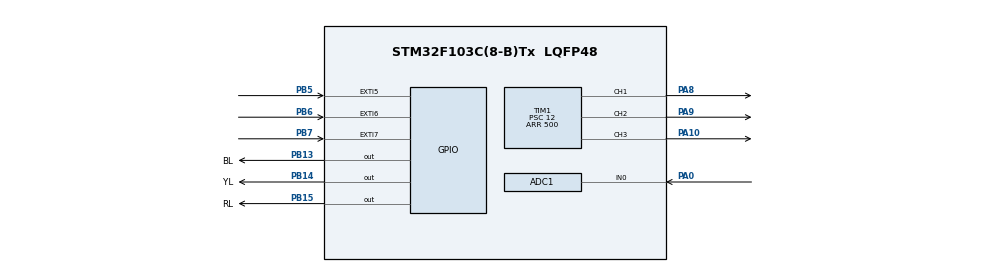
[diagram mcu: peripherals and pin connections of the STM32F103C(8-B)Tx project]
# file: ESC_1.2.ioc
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ADC1.Channel-0\#ChannelRegularConversion=ADC_CHANNEL_0
ADC1.ContinuousConvMode=ENABLE
ADC1.NbrOfConversionFlag=1
ADC1.Rank-0\#ChannelRegularConversion=1
ADC1.SamplingTime-0\#ChannelRegularConversion=ADC_SAMPLETIME_1CYCLE_5
ADC1.master=1
Dma.ADC1.0.Direction=DMA_PERIPH_TO_MEMORY
Dma.ADC1.0.Instance=DMA1_Channel1
Dma.ADC1.0.MemDataAlignment=DMA_MDATAALIGN_HALFWORD
Dma.ADC1.0.MemInc=DMA_MINC_ENABLE
Dma.ADC1.0.Mode=DMA_CIRCULAR
Dma.ADC1.0.PeriphDataAlignment=DMA_PDATAALIGN_HALFWORD
Dma.ADC1.0.PeriphInc=DMA_PINC_DISABLE
Dma.ADC1.0.Priority=DMA_PRIORITY_LOW
Dma.Request0=ADC1
Mcu.Family=STM32F1
Mcu.Name=STM32F103C(8-B)Tx
Mcu.Package=LQFP48
NVIC.DMA1_Channel1_IRQn=true\:0\:0\:false\:false\:true\:false\:true
NVIC.EXTI9_5_IRQn=true\:0\:0\:false\:false\:true\:true\:true
NVIC.PriorityGroup=NVIC_PRIORITYGROUP_4
PA0-WKUP.Signal=ADCx_IN0
PA10.Signal=S_TIM1_CH3
PA13.Mode=Serial_Wire
PA13.Signal=SYS_JTMS-SWDIO
PA14.Mode=Serial_Wire
PA14.Signal=SYS_JTCK-SWCLK
PA8.Signal=S_TIM1_CH1
PA9.Signal=S_TIM1_CH2
PB13.GPIO_Label=BL
PB13.Signal=GPIO_Output
PB14.GPIO_Label=YL
PB14.Signal=GPIO_Output
PB15.GPIO_Label=RL
PB15.Signal=GPIO_Output
PB5.GPIO_ModeDefaultEXTI=GPIO_MODE_IT_RISING_FALLING
PB5.Signal=GPXTI5
PB6.GPIO_ModeDefaultEXTI=GPIO_MODE_IT_RISING_FALLING
PB6.Signal=GPXTI6
PB7.GPIO_ModeDefaultEXTI=GPIO_MODE_IT_RISING_FALLING
PB7.Signal=GPXTI7
PD0-OSC_IN.Mode=HSE-External-Oscillator
PD0-OSC_IN.Signal=RCC_OSC_IN
PD1-OSC_OUT.Mode=HSE-External-Oscillator
PD1-OSC_OUT.Signal=RCC_OSC_OUT
ProjectManager.HeapSize=0x200
ProjectManager.StackSize=0x400
ProjectManager.TargetToolchain=MDK-ARM V5.27
RCC.ADCPresc=RCC_ADCPCLK2_DIV6
RCC.AHBFreq_Value=72000000
RCC.APB1CLKDivider=RCC_HCLK_DIV2
RCC.APB1Freq_Value=36000000
RCC.APB1TimFreq_Value=72000000
RCC.APB2Freq_Value=72000000
RCC.APB2TimFreq_Value=72000000
RCC.HCLKFreq_Value=72000000
RCC.PLLMUL=RCC_PLL_MUL9
RCC.PLLSourceVirtual=RCC_PLLSOURCE_HSE
RCC.SYSCLKFreq_VALUE=72000000
RCC.SYSCLKSource=RCC_SYSCLKSOURCE_PLLCLK
RCC.USBFreq_Value=72000000
SH.ADCx_IN0.0=ADC1_IN0,IN0
SH.S_TIM1_CH1.0=TIM1_CH1,PWM Generation1 CH1
SH.S_TIM1_CH2.0=TIM1_CH2,PWM Generation2 CH2
SH.S_TIM1_CH3.0=TIM1_CH3,PWM Generation3 CH3
TIM1.AutoReloadPreload=TIM_AUTORELOAD_PRELOAD_ENABLE
TIM1.Channel-PWM\ Generation1\ CH1=TIM_CHANNEL_1
TIM1.Channel-PWM\ Generation2\ CH2=TIM_CHANNEL_2
TIM1.Channel-PWM\ Generation3\ CH3=TIM_CHANNEL_3
TIM1.Period=500
TIM1.Prescaler=12
TIM1.Pulse-PWM\ Generation1\ CH1=200
TIM1.Pulse-PWM\ Generation2\ CH2=200
TIM1.Pulse-PWM\ Generation3\ CH3=200
VP_TIM1_VS_ClockSourceINT.Mode=Internal
board=custom

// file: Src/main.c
/* USER CODE BEGIN Header */
/**
  ******************************************************************************
  * @file           : main.c
  * @brief          : Main program body
  ******************************************************************************
  * @attention
  *
  * <h2><center>&copy; Copyright (c) 2020 STMicroelectronics.
  * All rights reserved.</center></h2>
  *
  * This software component is licensed by ST under BSD 3-Clause license,
  * the "License"; You may not use this file except in compliance with the
  * License. You may obtain a copy of the License at:
  *                        opensource.org/licenses/BSD-3-Clause
  *
  ******************************************************************************
  */
/* USER CODE END Header */

#include "main.h"

/* USER CODE BEGIN Includes */

#include "DMAInit.h"
#include "bldc.h"
/* USER CODE END Includes */

void SystemClock_Config(void);
static void MX_GPIO_Init(void);
static void MX_DMA_Init(void);
static void MX_TIM1_Init(void);
static void MX_ADC1_Init(void);
/* USER CODE BEGIN PFP */
void User_IT_Handler(void);
/* USER CODE END PFP */

/* USER CODE BEGIN 0 */
void User_IT_Handler(void){

	MotorCommutation();

}
/* USER CODE END 0 */

int main(void)
{

  /* MCU Configuration--------------------------------------------------------*/

  /* Reset of all peripherals, Initializes the Flash interface and the Systick. */

  LL_APB2_GRP1_EnableClock(LL_APB2_GRP1_PERIPH_AFIO);
  LL_APB1_GRP1_EnableClock(LL_APB1_GRP1_PERIPH_PWR);

  NVIC_SetPriorityGrouping(NVIC_PRIORITYGROUP_4);

  /* System interrupt init*/

  /** NOJTAG: JTAG-DP Disabled and SW-DP Enabled
  */
  LL_GPIO_AF_Remap_SWJ_NOJTAG();

  /* Configure the system clock */
  SystemClock_Config();

  /* Initialize all configured peripherals */
  MX_GPIO_Init();
  MX_DMA_Init();
  MX_TIM1_Init();
  MX_ADC1_Init();
  /* USER CODE BEGIN 2 */
	LL_TIM_EnableCounter(TIM1);
	MotorInit();
	//LL_TIM_EnableAutomaticOutput(TIM1);
	//LL_TIM_CC_EnableChannel(TIM1, LL_TIM_CHANNEL_CH1);
  /* USER CODE END 2 */

  /* Infinite loop */
  /* USER CODE BEGIN WHILE */
  while (1)
  {
			//MotorCommutation();

    /* USER CODE END WHILE */

  }
}

void SystemClock_Config(void)
{
  LL_FLASH_SetLatency(LL_FLASH_LATENCY_2);

   if(LL_FLASH_GetLatency() != LL_FLASH_LATENCY_2)
  {
    Error_Handler();
  }
  LL_RCC_HSE_Enable();

   /* Wait till HSE is ready */
  while(LL_RCC_HSE_IsReady() != 1)
  {

  }
  LL_RCC_PLL_ConfigDomain_SYS(LL_RCC_PLLSOURCE_HSE_DIV_1, LL_RCC_PLL_MUL_9);
  LL_RCC_PLL_Enable();

   /* Wait till PLL is ready */
  while(LL_RCC_PLL_IsReady() != 1)
  {

  }
  LL_RCC_SetAHBPrescaler(LL_RCC_SYSCLK_DIV_1);
  LL_RCC_SetAPB1Prescaler(LL_RCC_APB1_DIV_2);
  LL_RCC_SetAPB2Prescaler(LL_RCC_APB2_DIV_1);
  LL_RCC_SetSysClkSource(LL_RCC_SYS_CLKSOURCE_PLL);

   /* Wait till System clock is ready */
  while(LL_RCC_GetSysClkSource() != LL_RCC_SYS_CLKSOURCE_STATUS_PLL)
  {

  }
  LL_Init1msTick(72000000);
  LL_SetSystemCoreClock(72000000);
  LL_RCC_SetADCClockSource(LL_RCC_ADC_CLKSRC_PCLK2_DIV_6);
}

static void MX_ADC1_Init(void)
{

  LL_ADC_InitTypeDef ADC_InitStruct = {0};
  LL_ADC_CommonInitTypeDef ADC_CommonInitStruct = {0};
  LL_ADC_REG_InitTypeDef ADC_REG_InitStruct = {0};

  LL_GPIO_InitTypeDef GPIO_InitStruct = {0};

  /* Peripheral clock enable */
  LL_APB2_GRP1_EnableClock(LL_APB2_GRP1_PERIPH_ADC1);

  LL_APB2_GRP1_EnableClock(LL_APB2_GRP1_PERIPH_GPIOA);
  /**ADC1 GPIO Configuration
  PA0-WKUP   ------> ADC1_IN0
  */
  GPIO_InitStruct.Pin = LL_GPIO_PIN_0;
  GPIO_InitStruct.Mode = LL_GPIO_MODE_ANALOG;
  LL_GPIO_Init(GPIOA, &GPIO_InitStruct);

  /* ADC1 DMA Init */

  /* ADC1 Init */
  LL_DMA_SetDataTransferDirection(DMA1, LL_DMA_CHANNEL_1, LL_DMA_DIRECTION_PERIPH_TO_MEMORY);

  LL_DMA_SetChannelPriorityLevel(DMA1, LL_DMA_CHANNEL_1, LL_DMA_PRIORITY_LOW);

  LL_DMA_SetMode(DMA1, LL_DMA_CHANNEL_1, LL_DMA_MODE_CIRCULAR);

  LL_DMA_SetPeriphIncMode(DMA1, LL_DMA_CHANNEL_1, LL_DMA_PERIPH_NOINCREMENT);

  LL_DMA_SetMemoryIncMode(DMA1, LL_DMA_CHANNEL_1, LL_DMA_MEMORY_INCREMENT);

  LL_DMA_SetPeriphSize(DMA1, LL_DMA_CHANNEL_1, LL_DMA_PDATAALIGN_HALFWORD);

  LL_DMA_SetMemorySize(DMA1, LL_DMA_CHANNEL_1, LL_DMA_MDATAALIGN_HALFWORD);

  /** Common config
  */
  ADC_InitStruct.DataAlignment = LL_ADC_DATA_ALIGN_RIGHT;
  ADC_InitStruct.SequencersScanMode = LL_ADC_SEQ_SCAN_DISABLE;
  LL_ADC_Init(ADC1, &ADC_InitStruct);
  ADC_CommonInitStruct.Multimode = LL_ADC_MULTI_INDEPENDENT;
  LL_ADC_CommonInit(__LL_ADC_COMMON_INSTANCE(ADC1), &ADC_CommonInitStruct);
  ADC_REG_InitStruct.TriggerSource = LL_ADC_REG_TRIG_SOFTWARE;
  ADC_REG_InitStruct.SequencerLength = LL_ADC_REG_SEQ_SCAN_DISABLE;
  ADC_REG_InitStruct.SequencerDiscont = LL_ADC_REG_SEQ_DISCONT_DISABLE;
  ADC_REG_InitStruct.ContinuousMode = LL_ADC_REG_CONV_CONTINUOUS;
  ADC_REG_InitStruct.DMATransfer = LL_ADC_REG_DMA_TRANSFER_UNLIMITED;
  LL_ADC_REG_Init(ADC1, &ADC_REG_InitStruct);
  /** Configure Regular Channel
  */
  LL_ADC_REG_SetSequencerRanks(ADC1, LL_ADC_REG_RANK_1, LL_ADC_CHANNEL_0);
  LL_ADC_SetChannelSamplingTime(ADC1, LL_ADC_CHANNEL_0, LL_ADC_SAMPLINGTIME_1CYCLE_5);

}

static void MX_TIM1_Init(void)
{

  LL_TIM_InitTypeDef TIM_InitStruct = {0};
  LL_TIM_OC_InitTypeDef TIM_OC_InitStruct = {0};
  LL_TIM_BDTR_InitTypeDef TIM_BDTRInitStruct = {0};

  LL_GPIO_InitTypeDef GPIO_InitStruct = {0};

  /* Peripheral clock enable */
  LL_APB2_GRP1_EnableClock(LL_APB2_GRP1_PERIPH_TIM1);

  TIM_InitStruct.Prescaler = 12;
  TIM_InitStruct.CounterMode = LL_TIM_COUNTERMODE_UP;
  TIM_InitStruct.Autoreload = 500;
  TIM_InitStruct.ClockDivision = LL_TIM_CLOCKDIVISION_DIV1;
  TIM_InitStruct.RepetitionCounter = 0;
  LL_TIM_Init(TIM1, &TIM_InitStruct);
  LL_TIM_EnableARRPreload(TIM1);
  LL_TIM_SetClockSource(TIM1, LL_TIM_CLOCKSOURCE_INTERNAL);
  LL_TIM_OC_EnablePreload(TIM1, LL_TIM_CHANNEL_CH1);
  TIM_OC_InitStruct.OCMode = LL_TIM_OCMODE_PWM1;
  TIM_OC_InitStruct.OCState = LL_TIM_OCSTATE_DISABLE;
  TIM_OC_InitStruct.OCNState = LL_TIM_OCSTATE_DISABLE;
  TIM_OC_InitStruct.CompareValue = 200;
  TIM_OC_InitStruct.OCPolarity = LL_TIM_OCPOLARITY_HIGH;
  TIM_OC_InitStruct.OCNPolarity = LL_TIM_OCPOLARITY_HIGH;
  TIM_OC_InitStruct.OCIdleState = LL_TIM_OCIDLESTATE_LOW;
  TIM_OC_InitStruct.OCNIdleState = LL_TIM_OCIDLESTATE_LOW;
  LL_TIM_OC_Init(TIM1, LL_TIM_CHANNEL_CH1, &TIM_OC_InitStruct);
  LL_TIM_OC_DisableFast(TIM1, LL_TIM_CHANNEL_CH1);
  LL_TIM_OC_EnablePreload(TIM1, LL_TIM_CHANNEL_CH2);
  TIM_OC_InitStruct.OCState = LL_TIM_OCSTATE_DISABLE;
  TIM_OC_InitStruct.OCNState = LL_TIM_OCSTATE_DISABLE;
  LL_TIM_OC_Init(TIM1, LL_TIM_CHANNEL_CH2, &TIM_OC_InitStruct);
  LL_TIM_OC_DisableFast(TIM1, LL_TIM_CHANNEL_CH2);
  LL_TIM_OC_EnablePreload(TIM1, LL_TIM_CHANNEL_CH3);
  TIM_OC_InitStruct.OCState = LL_TIM_OCSTATE_DISABLE;
  TIM_OC_InitStruct.OCNState = LL_TIM_OCSTATE_DISABLE;
  LL_TIM_OC_Init(TIM1, LL_TIM_CHANNEL_CH3, &TIM_OC_InitStruct);
  LL_TIM_OC_DisableFast(TIM1, LL_TIM_CHANNEL_CH3);
  LL_TIM_SetTriggerOutput(TIM1, LL_TIM_TRGO_RESET);
  LL_TIM_DisableMasterSlaveMode(TIM1);
  TIM_BDTRInitStruct.OSSRState = LL_TIM_OSSR_DISABLE;
  TIM_BDTRInitStruct.OSSIState = LL_TIM_OSSI_DISABLE;
  TIM_BDTRInitStruct.LockLevel = LL_TIM_LOCKLEVEL_OFF;
  TIM_BDTRInitStruct.DeadTime = 0;
  TIM_BDTRInitStruct.BreakState = LL_TIM_BREAK_DISABLE;
  TIM_BDTRInitStruct.BreakPolarity = LL_TIM_BREAK_POLARITY_HIGH;
  TIM_BDTRInitStruct.AutomaticOutput = LL_TIM_AUTOMATICOUTPUT_DISABLE;
  LL_TIM_BDTR_Init(TIM1, &TIM_BDTRInitStruct);
  LL_APB2_GRP1_EnableClock(LL_APB2_GRP1_PERIPH_GPIOA);
  /**TIM1 GPIO Configuration
  PA8   ------> TIM1_CH1
  PA9   ------> TIM1_CH2
  PA10   ------> TIM1_CH3
  */
  GPIO_InitStruct.Pin = LL_GPIO_PIN_8|LL_GPIO_PIN_9|LL_GPIO_PIN_10;
  GPIO_InitStruct.Mode = LL_GPIO_MODE_ALTERNATE;
  GPIO_InitStruct.Speed = LL_GPIO_SPEED_FREQ_LOW;
  GPIO_InitStruct.OutputType = LL_GPIO_OUTPUT_PUSHPULL;
  LL_GPIO_Init(GPIOA, &GPIO_InitStruct);

}

static void MX_DMA_Init(void)
{

  /* Init with LL driver */
  /* DMA controller clock enable */
  LL_AHB1_GRP1_EnableClock(LL_AHB1_GRP1_PERIPH_DMA1);

  /* DMA interrupt init */
  /* DMA1_Channel1_IRQn interrupt configuration */
  NVIC_SetPriority(DMA1_Channel1_IRQn, NVIC_EncodePriority(NVIC_GetPriorityGrouping(),0, 0));
  NVIC_EnableIRQ(DMA1_Channel1_IRQn);

}

static void MX_GPIO_Init(void)
{
  LL_EXTI_InitTypeDef EXTI_InitStruct = {0};
  LL_GPIO_InitTypeDef GPIO_InitStruct = {0};

  /* GPIO Ports Clock Enable */
  LL_APB2_GRP1_EnableClock(LL_APB2_GRP1_PERIPH_GPIOD);
  LL_APB2_GRP1_EnableClock(LL_APB2_GRP1_PERIPH_GPIOA);
  LL_APB2_GRP1_EnableClock(LL_APB2_GRP1_PERIPH_GPIOB);

  /**/
  LL_GPIO_ResetOutputPin(GPIOB, BL_Pin|YL_Pin|RL_Pin);

  /**/
  GPIO_InitStruct.Pin = BL_Pin|YL_Pin|RL_Pin;
  GPIO_InitStruct.Mode = LL_GPIO_MODE_OUTPUT;
  GPIO_InitStruct.Speed = LL_GPIO_SPEED_FREQ_LOW;
  GPIO_InitStruct.OutputType = LL_GPIO_OUTPUT_PUSHPULL;
  LL_GPIO_Init(GPIOB, &GPIO_InitStruct);

  /**/
  LL_GPIO_AF_SetEXTISource(LL_GPIO_AF_EXTI_PORTB, LL_GPIO_AF_EXTI_LINE5);

  /**/
  LL_GPIO_AF_SetEXTISource(LL_GPIO_AF_EXTI_PORTB, LL_GPIO_AF_EXTI_LINE6);

  /**/
  LL_GPIO_AF_SetEXTISource(LL_GPIO_AF_EXTI_PORTB, LL_GPIO_AF_EXTI_LINE7);

  /**/
  EXTI_InitStruct.Line_0_31 = LL_EXTI_LINE_5;
  EXTI_InitStruct.LineCommand = ENABLE;
  EXTI_InitStruct.Mode = LL_EXTI_MODE_IT;
  EXTI_InitStruct.Trigger = LL_EXTI_TRIGGER_RISING_FALLING;
  LL_EXTI_Init(&EXTI_InitStruct);

  /**/
  EXTI_InitStruct.Line_0_31 = LL_EXTI_LINE_6;
  EXTI_InitStruct.LineCommand = ENABLE;
  EXTI_InitStruct.Mode = LL_EXTI_MODE_IT;
  EXTI_InitStruct.Trigger = LL_EXTI_TRIGGER_RISING_FALLING;
  LL_EXTI_Init(&EXTI_InitStruct);

  /**/
  EXTI_InitStruct.Line_0_31 = LL_EXTI_LINE_7;
  EXTI_InitStruct.LineCommand = ENABLE;
  EXTI_InitStruct.Mode = LL_EXTI_MODE_IT;
  EXTI_InitStruct.Trigger = LL_EXTI_TRIGGER_RISING_FALLING;
  LL_EXTI_Init(&EXTI_InitStruct);

  /**/
  LL_GPIO_SetPinMode(GPIOB, LL_GPIO_PIN_5, LL_GPIO_MODE_FLOATING);

  /**/
  LL_GPIO_SetPinMode(GPIOB, LL_GPIO_PIN_6, LL_GPIO_MODE_FLOATING);

  /**/
  LL_GPIO_SetPinMode(GPIOB, LL_GPIO_PIN_7, LL_GPIO_MODE_FLOATING);

  /* EXTI interrupt init*/
  NVIC_SetPriority(EXTI9_5_IRQn, NVIC_EncodePriority(NVIC_GetPriorityGrouping(),0, 0));
  NVIC_EnableIRQ(EXTI9_5_IRQn);

}

void Error_Handler(void)
{
}

/************************ (C) COPYRIGHT STMicroelectronics *****END OF FILE****/
